VERSION ""

NS_ :

BS_:

BU_: ECU Tool

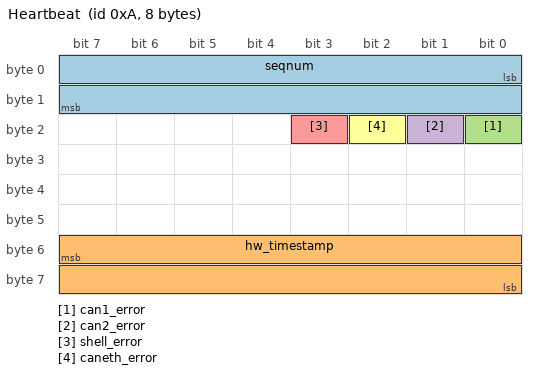
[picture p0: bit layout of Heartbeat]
BO_ 10 Heartbeat: 8 ECU
 SG_ seqnum : 0|16@1+ (1,0) [0|65535] ""  ECU
 SG_ hw_timestamp : 55|16@0+ (1,0) [0|65535] "" Vector__XXX
 SG_ can1_error : 16|1@1+ (1,0) [0|0] "" Vector__XXX
 SG_ can2_error : 17|1@1+ (1,0) [0|0] "" Vector__XXX
 SG_ shell_error : 19|1@1+ (1,0) [0|0] "" Vector__XXX
 SG_ caneth_error : 18|1@1+ (1,0) [0|0] "" Vector__XXX

BO_ 11 DoWork0: 8 Tool
 SG_ counter : 0|8@1+ (1,0) [0|255] "" Vector__XXX

CM_ BU_ ECU "The ECU";
CM_ BU_ Tool "User CAN interface";
CM_ SG_ 10 hw_timestamp "hardware_timestamp";
CM_ BO_ 11 "Invoke the worker0 stask";
